# STM32L0x0 register map
File version: 1.1
CPU: CM0+ r0p0, little endian, MPU, no FPU, 4 interrupt priority bits
Registers are 32-bit, read-write, reset 0x0 unless marked. A register's access mark holds for its fields unless they carry their own. Offsets are from the block's base; [hi:lo] are bit positions.

## I2C1 — Inter-integrated circuit
Base 0x40005400
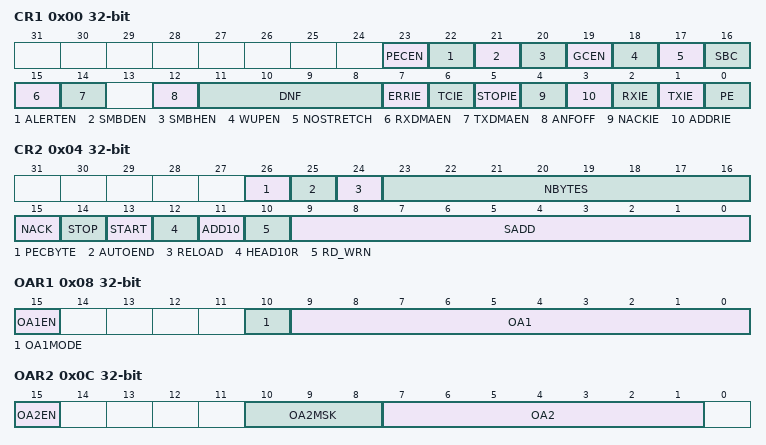
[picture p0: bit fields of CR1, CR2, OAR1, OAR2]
0x00 CR1 — Control register 1
  [23] PECEN — PEC enable
  [22] ALERTEN — SMBUS alert enable
  [21] SMBDEN — SMBus Device Default address enable
  [20] SMBHEN — SMBus Host address enable
  [19] GCEN — General call enable
  [18] WUPEN — Wakeup from STOP enable
  [17] NOSTRETCH — Clock stretching disable
  [16] SBC — Slave byte control
  [15] RXDMAEN — DMA reception requests enable
  [14] TXDMAEN — DMA transmission requests enable
  [12] ANFOFF — Analog noise filter OFF
  [11:8] DNF — Digital noise filter
  [7] ERRIE — Error interrupts enable
  [6] TCIE — Transfer Complete interrupt enable
  [5] STOPIE — STOP detection Interrupt enable
  [4] NACKIE — Not acknowledge received interrupt enable
  [3] ADDRIE — Address match interrupt enable (slave only)
  [2] RXIE — RX Interrupt enable
  [1] TXIE — TX Interrupt enable
  [0] PE — Peripheral enable
0x04 CR2 — Control register 2
  [26] PECBYTE — Packet error checking byte
  [25] AUTOEND — Automatic end mode (master mode)
  [24] RELOAD — NBYTES reload mode
  [23:16] NBYTES — Number of bytes
  [15] NACK — NACK generation (slave mode)
  [14] STOP — Stop generation (master mode)
  [13] START — Start generation
  [12] HEAD10R — 10-bit address header only read direction (master receiver mode)
  [11] ADD10 — 10-bit addressing mode (master mode)
  [10] RD_WRN — Transfer direction (master mode)
  [9:0] SADD — Slave address bit (master mode)
0x08 OAR1 — Own address register 1
  [15] OA1EN — Own Address 1 enable
  [10] OA1MODE — Own Address 1 10-bit mode
  [9:0] OA1 — Interface address
0x0C OAR2 — Own address register 2
  [15] OA2EN — Own Address 2 enable
  [10:8] OA2MSK — Own Address 2 masks
  [7:1] OA2 — Interface address
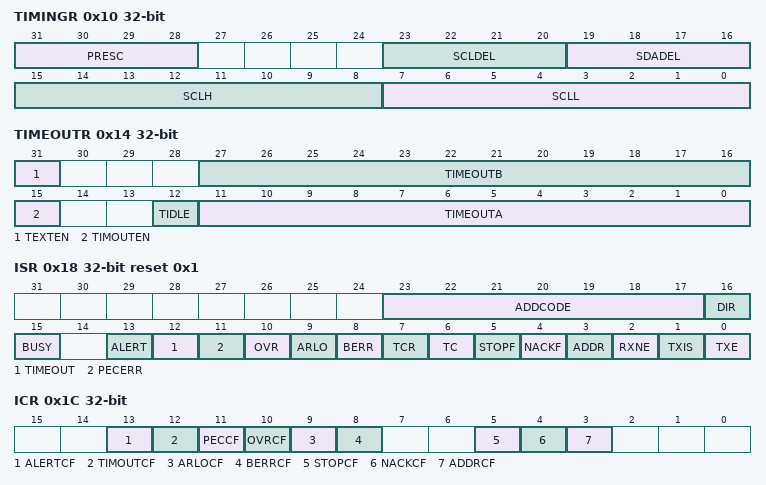
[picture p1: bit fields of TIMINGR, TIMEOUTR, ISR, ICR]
0x10 TIMINGR — Timing register
  [31:28] PRESC — Timing prescaler
  [23:20] SCLDEL — Data setup time
  [19:16] SDADEL — Data hold time
  [15:8] SCLH — SCL high period (master mode)
  [7:0] SCLL — SCL low period (master mode)
0x14 TIMEOUTR — Status register 1
  [31] TEXTEN — Extended clock timeout enable
  [27:16] TIMEOUTB — Bus timeout B
  [15] TIMOUTEN — Clock timeout enable
  [12] TIDLE — Idle clock timeout detection
  [11:0] TIMEOUTA — Bus timeout A
0x18 ISR access per field reset 0x1 — Interrupt and Status register
  [23:17] ADDCODE ro — Address match code (Slave mode)
  [16] DIR ro — Transfer direction (Slave mode)
  [15] BUSY ro — Bus busy
  [13] ALERT ro — SMBus alert
  [12] TIMEOUT ro — Timeout or t_low detection flag
  [11] PECERR ro — PEC Error in reception
  [10] OVR ro — Overrun/Underrun (slave mode)
  [9] ARLO ro — Arbitration lost
  [8] BERR ro — Bus error
  [7] TCR ro — Transfer Complete Reload
  [6] TC ro — Transfer Complete (master mode)
  [5] STOPF ro — Stop detection flag
  [4] NACKF ro — Not acknowledge received flag
  [3] ADDR ro — Address matched (slave mode)
  [2] RXNE ro — Receive data register not empty (receivers)
  [1] TXIS rw — Transmit interrupt status (transmitters)
  [0] TXE rw — Transmit data register empty (transmitters)
0x1C ICR wo — Interrupt clear register
  [13] ALERTCF — Alert flag clear
  [12] TIMOUTCF — Timeout detection flag clear
  [11] PECCF — PEC Error flag clear
  [10] OVRCF — Overrun/Underrun flag clear
  [9] ARLOCF — Arbitration lost flag clear
  [8] BERRCF — Bus error flag clear
  [5] STOPCF — Stop detection flag clear
  [4] NACKCF — Not Acknowledge flag clear
  [3] ADDRCF — Address Matched flag clear
0x20 PECR ro — PEC register
  [7:0] PEC — Packet error checking register
0x24 RXDR ro — Receive data register
  [7:0] RXDATA — 8-bit receive data
0x28 TXDR — Transmit data register
  [7:0] TXDATA — 8-bit transmit data

## PWR — Power control
Base 0x40007000
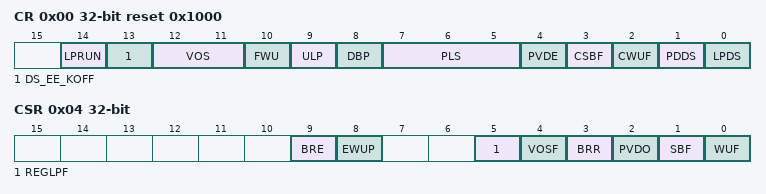
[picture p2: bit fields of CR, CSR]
0x00 CR reset 0x1000 — power control register
  [14] LPRUN — Low power run mode
  [13] DS_EE_KOFF — Deep sleep mode with Flash memory kept off
  [12:11] VOS — Voltage scaling range selection
  [10] FWU — Fast wakeup
  [9] ULP — Ultra-low-power mode
  [8] DBP — Disable backup domain write protection
  [7:5] PLS — PVD level selection
  [4] PVDE — Power voltage detector enable
  [3] CSBF — Clear standby flag
  [2] CWUF — Clear wakeup flag
  [1] PDDS — Power down deepsleep
  [0] LPDS — Low-power deep sleep
0x04 CSR access per field — power control/status register
  [9] BRE rw — Backup regulator enable
  [8] EWUP rw — Enable WKUP pin
  [5] REGLPF ro — Regulator LP flag
  [4] VOSF ro — Voltage Scaling select flag
  [3] BRR ro — Backup regulator ready
  [2] PVDO ro — PVD output
  [1] SBF ro — Standby flag
  [0] WUF ro — Wakeup flag
